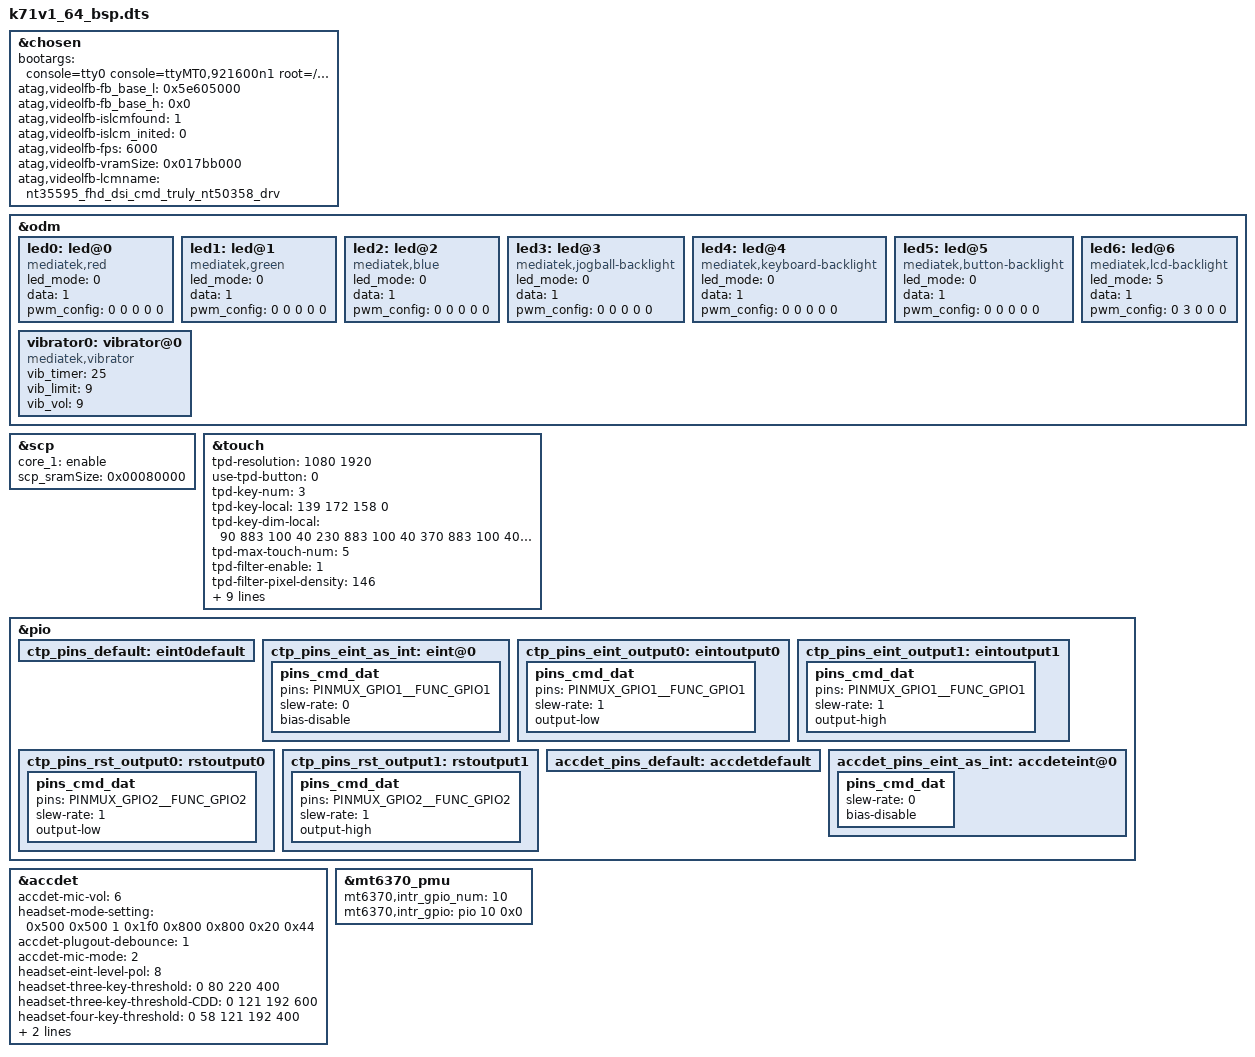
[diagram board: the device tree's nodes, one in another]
/dts-v1/;
/plugin/;
#include <dt-bindings/interrupt-controller/irq.h>
#include <dt-bindings/interrupt-controller/arm-gic.h>
#include <dt-bindings/pinctrl/mt6771-pinfunc.h>

/* chosen */
&chosen {
	bootargs = "console=tty0 console=ttyMT0,921600n1 root=/dev/ram \
initrd=0x55000000,0x3000000 loglevel=8 \
androidboot.selinux=permissive androidboot.hardware=mt6771 \
initcall_debug=1";
	/* fpga may has no lk, we need to specify display info here */
	/* fb buffer is reserved using this dts by memory node above */

	atag,videolfb-fb_base_l = <0x5e605000>;
	atag,videolfb-fb_base_h = <0x0>;
	atag,videolfb-islcmfound = <1>;
	atag,videolfb-islcm_inited = <0>;
	atag,videolfb-fps= <6000>;
	atag,videolfb-vramSize= <0x017bb000>;
	atag,videolfb-lcmname= "nt35595_fhd_dsi_cmd_truly_nt50358_drv";
};

&odm {
	led0:led@0 {
		compatible = "mediatek,red";
		led_mode = <0>;
		data = <1>;
		pwm_config = <0 0 0 0 0>;
	};
	led1:led@1 {
		compatible = "mediatek,green";
		led_mode = <0>;
		data = <1>;
		pwm_config = <0 0 0 0 0>;
	};
	led2:led@2 {
		compatible = "mediatek,blue";
		led_mode = <0>;
		data = <1>;
		pwm_config = <0 0 0 0 0>;
	};
	led3:led@3 {
		compatible = "mediatek,jogball-backlight";
		led_mode = <0>;
		data = <1>;
		pwm_config = <0 0 0 0 0>;
	};
	led4:led@4 {
		compatible = "mediatek,keyboard-backlight";
		led_mode = <0>;
		data = <1>;
		pwm_config = <0 0 0 0 0>;
	};
	led5:led@5 {
		compatible = "mediatek,button-backlight";
		led_mode = <0>;
		data = <1>;
		pwm_config = <0 0 0 0 0>;
	};
	led6:led@6 {
		compatible = "mediatek,lcd-backlight";
		led_mode = <5>;
		data = <1>;
		pwm_config = <0 3 0 0 0>;
	};
	vibrator0:vibrator@0 {
		compatible = "mediatek,vibrator";
		vib_timer = <25>;
		vib_limit = <9>;
		vib_vol= <9>;
	};
};

&scp {
	core_1 = "enable";
	scp_sramSize = <0x00080000>;     /* scp_A_sram_size */
};

/* TOUCH start */
&touch {
	tpd-resolution = <1080 1920>;
	use-tpd-button = <0>;
	tpd-key-num = <3>;
	tpd-key-local= <139 172 158 0>;
	tpd-key-dim-local = <90 883 100 40 230 883 100 40 370 883 100 40 0 0 0 0>;
	tpd-max-touch-num = <5>;
	tpd-filter-enable = <1>;
	tpd-filter-pixel-density = <146>;
	tpd-filter-custom-prameters = <0 0 0 0 0 0 0 0 0 0 0 0>;
	tpd-filter-custom-speed = <0 0 0>;
	pinctrl-names = "default", "state_eint_as_int", "state_eint_output0", "state_eint_output1",
		"state_rst_output0", "state_rst_output1";
	pinctrl-0 = <&ctp_pins_default>;
	pinctrl-1 = <&ctp_pins_eint_as_int>;
	pinctrl-2 = <&ctp_pins_eint_output0>;
	pinctrl-3 = <&ctp_pins_eint_output1>;
	pinctrl-4 = <&ctp_pins_rst_output0>;
	pinctrl-5 = <&ctp_pins_rst_output1>;
	status = "okay";
};
&pio {
	ctp_pins_default: eint0default {
	};
	ctp_pins_eint_as_int: eint@0 {
		pins_cmd_dat {
			pins = <PINMUX_GPIO1__FUNC_GPIO1>;
			slew-rate = <0>;
			bias-disable;
		};
	};
	ctp_pins_eint_output0: eintoutput0 {
		pins_cmd_dat {
			pins = <PINMUX_GPIO1__FUNC_GPIO1>;
			slew-rate = <1>;
			output-low;
		};
	};
	ctp_pins_eint_output1: eintoutput1 {
		pins_cmd_dat {
			pins = <PINMUX_GPIO1__FUNC_GPIO1>;
			slew-rate = <1>;
			output-high;
		};
	};
	ctp_pins_rst_output0: rstoutput0 {
		pins_cmd_dat {
			pins = <PINMUX_GPIO2__FUNC_GPIO2>;
			slew-rate = <1>;
			output-low;
		};
	};
	ctp_pins_rst_output1: rstoutput1 {
		pins_cmd_dat {
			pins = <PINMUX_GPIO2__FUNC_GPIO2>;
			slew-rate = <1>;
			output-high;
		};
	};
};
/* TOUCH end */

/* accdet start */
&accdet {
	/* accdet micbias voltage: 0x07,2.7v;0x05,2.5v;0x02,1.9v */
	accdet-mic-vol = <6>;
	headset-mode-setting = <0x500 0x500 1 0x1f0 0x800 0x800 0x20 0x44>;
	accdet-plugout-debounce = <1>;
	/*1:ACC mode, 2:low cost without in bias, 6:low cost with in bias*/
	accdet-mic-mode = <2>;
	/* eint_level_trigger: 8,LEVEL_LOW(default);4,LEVEL_HIGH;others,LEVEL_LOW */
	headset-eint-level-pol = <8>;
	/*0--MD_MAX--UP_MAX--DW_MAX*/
	headset-three-key-threshold = <0 80 220 400>;
	headset-three-key-threshold-CDD = <0 121 192 600>;
	/*0--MD_MAX--VOICE_MAX--UP_MAX--DW_MAX*/
	headset-four-key-threshold = <0 58 121 192 400>;
	/* ACCDET GPIO standardization ACC mode no use */
	pinctrl-names = "default", "state_eint_as_int";
	pinctrl-0 = <&accdet_pins_default>;
	pinctrl-1 = <&accdet_pins_eint_as_int>;
	status = "okay";
};
&pio {
	accdet_pins_default: accdetdefault {
	};
	accdet_pins_eint_as_int: accdeteint@0 {
		pins_cmd_dat {
			/*pins = <PINMUX_GPIO7__FUNC_GPIO7>;*/
			slew-rate = <0>;
			bias-disable;
		};
	};
};
/* accdet end */

&mt6370_pmu {
	mt6370,intr_gpio_num = <10>; /* direct defined GPIO num */
	mt6370,intr_gpio = <&pio 10 0x0>;
};

#if 0
#include <k71v1_64_bsp/cust.dtsi>
/*End of this file, DO NOT ADD ANYTHING HERE*/
#endif


